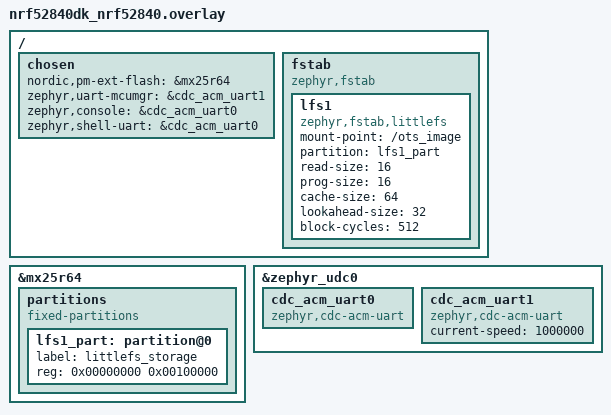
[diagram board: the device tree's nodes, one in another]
/ {
	chosen {
		nordic,pm-ext-flash = &mx25r64;
		zephyr,uart-mcumgr = &cdc_acm_uart1;
		zephyr,console = &cdc_acm_uart0;
		zephyr,shell-uart = &cdc_acm_uart0;
	};
};

/ {
	fstab {
		compatible = "zephyr,fstab";
		lfs1: lfs1 {
			compatible = "zephyr,fstab,littlefs";
			mount-point = "/ots_image";
			partition = <&lfs1_part>;
			read-size = <16>;
			prog-size = <16>;
			cache-size = <64>;
			lookahead-size = <32>;
			block-cycles = <512>;
		};
	};
};

&mx25r64 {
	partitions {
		compatible = "fixed-partitions";
		#address-cells = <1>;
		#size-cells = <1>;

		lfs1_part: partition@0 {
			label = "littlefs_storage";
			reg = <0x00000000 0x00100000>;
		};
	};
};

&zephyr_udc0 {
	cdc_acm_uart0: cdc_acm_uart0 {
		compatible = "zephyr,cdc-acm-uart";
	};

	cdc_acm_uart1: cdc_acm_uart1 {
		current-speed=<1000000>;
		compatible = "zephyr,cdc-acm-uart";
	};

};
